# CEC1734_S0_2ZW register map
Vendor: Microchip Technology; Series: CEC; File version: 0
CPU: CM4 r1p0, little endian, MPU, FPU, 3 interrupt priority bits, 196 interrupts
Registers are 32-bit, read-write, reset 0x0 unless marked. A register's access mark holds for its fields unless they carry their own. Offsets are from the block's base; [hi:lo] are bit positions.

## SPT0 — SPI Peripheral Target Register.
Base 0x40007000; register names take the prefix SPT_
Same registers: SPT1 0x40006C00
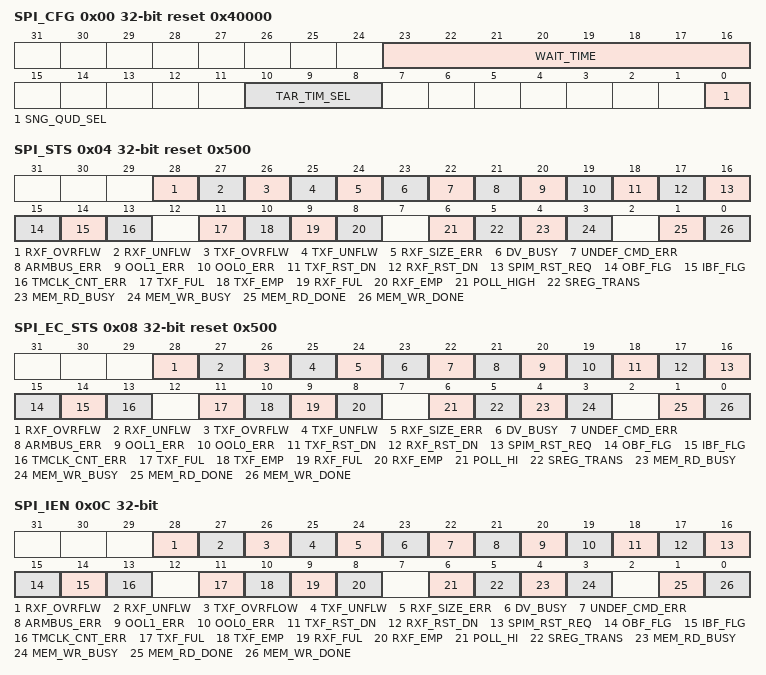
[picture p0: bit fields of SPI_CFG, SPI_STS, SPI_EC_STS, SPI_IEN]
0x00 SPI_CFG reset 0x40000 — SPI Peripheral Target Communication Configuration Register.
  [23:16] WAIT_TIME — These bits set the amount of wait time in cycles before transmitting data back to master. During this wait time status bits will be transmitted
  [10:8] TAR_TIM_SEL — Turn Around Time select for Quad wire mode. 0h = 1 cycle. 1h = 2 cycles. 2h = 4 cycles. 3h = 8 cycles. Other values are reserved.
    0=TAR_TIME_1_CYCLE (1 cycle); 1=TAR_TIME_2_CYCLE (2 cycle); 2=TAR_TIME_4_CYCLE (4 cycle); 3=TAR_TIME_8_CYCLE (8 cycle)
  [0] SNG_QUD_SEL — This field defines the Single / Quad Wire mode of operation for SPI Peripheral Target block. 0 = Single Wire Slave SPI block operation. 1 = Quad Wire Slave SPI block operation.
0x04 SPI_STS reset 0x500 — SPI Peripheral Target Status Register.
  [28] RXF_OVRFLW — If SPI Master writes more than the space in the FIFO, the FIFO will flag an overflow error and data will not be stored.
  [27] RXF_UNFLW — If the SPI Peripheral Target reads RX FIFO when it is empty, RX FIFO Underflow flag will be set. This condition will never happen under normal situation.
  [26] TXF_OVRFLW — If Master doesn't read all of the data it requested from the posted read block cycle, than data will still be left in the FIFO. This will cause misalignment with the following transactions and a new read cycle can cause overflow.
  [25] TXF_UNFLW — If Master reads more than what is in FIFO, FIFO will flag an underflow error and the data returned will just be the last valid pointer value.
  [24] RXF_SIZE_ERR — If size requested is more than what Master provided and the Master terminates early error flag shut down request signal to ARM Bus. Size requested is less than what Master provided -- ignored and continue transaction, may be taking in garbage.
  [23] DV_BUSY — If the Master requested a transaction whose destination is busy the request is ignored. Should use the poll or wait for interrupts.
  [22] UNDEF_CMD_ERR — Undefined Command Error: The command received from the master isn't defined.
  [21] ARMBUS_ERR — ARM Bus Error returned for the curren data transfer.
  [20] OOL1_ERR — This flag is set with the transfer address requested by the master is out of Limit 1 range or when the BAR is disabled.
  [19] OOL0_ERR — This flag is set with the transfer address requested by the master is out of Limit 0 range or when the BAR is disabled.
  [18] TXF_RST_DN — Set after the SPI Master initiates a TX FIFO reset and the reset has been processed. FIFO is cleared.
  [17] RXF_RST_DN — Set after the SPI Master initiates a RX FIFO reset and the reset has been processed. FIFO is cleared.
  [16] SPIM_RST_REQ — Set when the SPI Master Requested a Configuration Reset.
  [15] OBF_FLG — Set when the EC writes to the Output Buffer signaling there is data for the Host to read.
  [14] IBF_FLG — Set when the Host writes to the Input Buffer signaling there is data for the EC to read.
  [13] TMCLK_CNT_ERR — This bit is set when the SPI Clock Count Test Mode is set and there is an uneven amount of clocks.
  [11] TXF_FUL — The TX FIFO is full of data that was read from Memory.
  [10] TXF_EMP — Signifies SPI Master has read the data requested from Memory. Can be used to show there is data the SPI Master has requested and not been read yet. New read transactions will be aligned.
  [9] RXF_FUL — The RX FIFO is full of data to be written to Memory.
  [8] RXF_EMP — Signifies all Memory write transactions for the SPI Masters requested size have been performed. New transactions are allowed.
  [6] POLL_HIGH — If this bit is set, then something in the high 16-bit of status register is set and needs to be checked. SPI Master should take action to clear this.
  [5] SREG_TRANS — When an SREG transaction is currently being processed.
  [4] MEM_RD_BUSY — When an Memory Read transaction is currently being processed.
  [3] MEM_WR_BUSY — When an Memory Write transaction is currently being processed.
  [1] MEM_RD_DONE — When the ARM BUS side has fully finished writing the last written DWord to the FIFO for a set of data read from Memory for Posted Reads. - cleared with new Read request.
  [0] MEM_WR_DONE — When the ARM BUS side has fully finished the last transaction from the FIFO to write the data to Memory for Posted Writes . Clear with new Write request.
0x08 SPI_EC_STS reset 0x500 — SPI Peripheral Target EC Status Register.
  [28] RXF_OVRFLW — If SPI Master writes more than the space in the FIFO, the FIFO will flag an overflow error and data will not be stored.
  [27] RXF_UNFLW — If the SPI Peripheral Target reads RX FIFO when it is empty, RX FIFO Underflow flag will be set. This condition will never happen under normal situation.
  [26] TXF_OVRFLW — If Master doesn't read all of the data it requested from the posted read block cycle, than data will still be left in the FIFO. This will cause misalignment with the following transactions and a new read cycle can cause overflow.
  [25] TXF_UNFLW — If Master reads more than what is in FIFO, FIFO will flag an underflow error and the data returned will just be the last valid pointer value.
  [24] RXF_SIZE_ERR — If size requested is more than what Master provided and the Master terminates early error flag shut down request signal to ARM Bus. Size requested is less than what Master provided -- ignored and continue transaction, may be taking in garbage.
  [23] DV_BUSY — If the Master requested a transaction whose destination is busy the request is ignored. Should use the poll or wait for interrupts.
  [22] UNDEF_CMD_ERR — Undefined Command Error: The command received from the master isn't defined.
  [21] ARMBUS_ERR — ARM Bus Error returned for the curren data transfer.
  [20] OOL1_ERR — This flag is set with the transfer address requested by the master is out of Limit 1 range or when the BAR is disabled.
  [19] OOL0_ERR — This flag is set with the transfer address requested by the master is out of Limit 0 range or when the BAR is disabled.
  [18] TXF_RST_DN — Set after the SPI Master initiates a TX FIFO reset and the reset has been processed. FIFO is cleared.
  [17] RXF_RST_DN — Set after the SPI Master initiates a RX FIFO reset and the reset has been processed. FIFO is cleared.
  [16] SPIM_RST_REQ — Set when the SPI Master Requested a Configuration Reset.
  [15] OBF_FLG — Set when the EC writes to the Output Buffer signaling there is data for the Host to read.
  [14] IBF_FLG — Set when the Host writes to the Input Buffer signaling there is data for the EC to read.
  [13] TMCLK_CNT_ERR — This bit is set when the SPI Clock Count Test Mode is set and there is an uneven amount of clocks.
  [11] TXF_FUL — The TX FIFO is full of data that was read from Memory.
  [10] TXF_EMP — Signifies SPI Master has read the data requested from Memory. Can be used to show there is data the SPI Master has requested and not been read yet. New read transactions will be aligned.
  [9] RXF_FUL — The RX FIFO is full of data to be written to Memory.
  [8] RXF_EMP — Signifies all Memory write transactions for the SPI Masters requested size have been performed. New transactions are allowed.
  [6] POLL_HI — If this bit is set, then something in the high 16-bit of status register is set and needs to be checked. SPI Master should take action to clear this.
  [5] SREG_TRANS — When an SREG transaction is currently being processed.
  [4] MEM_RD_BUSY — When an Memory Read transaction is currently being processed.
  [3] MEM_WR_BUSY — When an Memory Write transaction is currently being processed.
  [1] MEM_RD_DONE — When the ARM BUS side has fully finished writing the last written DWord to the FIFO for a set of data read from Memory for Posted Reads. - cleared with new Read request.
  [0] MEM_WR_DONE — When the ARM BUS side has fully finished the last transaction from the FIFO to write the data to Memory for Posted Writes .- clear with new Write request.
0x0C SPI_IEN — SPI Peripheral Target Interrupt Enable Register.
  [28] RXF_OVRFLW — Enable RX FIFO Overflow Interrupt to SPI Master.
  [27] RXF_UNFLW — Enable RX FIFO Underflow Interrupt to SPI Master.
  [26] TXF_OVRFLOW — Enable TX FIFO Overflow Interrupt to SPI Master.
  [25] TXF_UNFLW — Enable TX FIFO Underflow Interrupt to SPI Master.
  [24] RXF_SIZE_ERR — Enable RX FIFO SIZE Error Interrupt to SPI Master.
  [23] DV_BUSY — Enable Device Busy Interrupt to SPI Master.
  [22] UNDEF_CMD_ERR — Enable Undefined Command Error Interrupt to SPI Master.
  [21] ARMBUS_ERR — Enable AHB BUS Error Interrupt to SPI Master.
  [20] OOL1_ERR — Enable Out Of Limit 1 Error Interrupt to SPI Master.
  [19] OOL0_ERR — Enable Out Of Limit 0 Error Interrupt to SPI Master.
  [18] TXF_RST_DN — Enable TX FIFO Reset Done Interrupt to SPI Master.
  [17] RXF_RST_DN — Enable RX FIFO Reset Done Interrupt to SPI Master.
  [16] SPIM_RST_REQ — Enable SPI Master Request Reset Interrupt to SPI Master.
  [15] OBF_FLG — Enable Output Buffer signaling Interrupt to SPI Master.
  [14] IBF_FLG — Enable Input Buffer Signaling Interrupt to SPI Master.
  [13] TMCLK_CNT_ERR — Enable Test Mode SPI Clock Count Error Interrupt to SPI Master.
  [11] TXF_FUL — Enable TX FIFI FULL Interrupt to SPI Master.
  [10] TXF_EMP — Enable TX FIFO Empty Interrupt to SPI Master.
  [9] RXF_FUL — Enable RX FIFO Full Interrupt to SPI Master.
  [8] RXF_EMP — Enable SREG RX FIFO Empty Interrupt to SPI Master.
  [6] POLL_HI — Enable Poll High Request Interrupt to SPI Master.
  [5] SREG_TRANS — Enable SREG Trans Busy Interrupt to SPI Master.
  [4] MEM_RD_BUSY — Enable Memory Read Busy Interrupt to SPI Master.
  [3] MEM_WR_BUSY — Enable Memory Write Busy Interrupt to SPI Master.
  [1] MEM_RD_DONE — Enable Memory Read Done Interrupt to SPI Master.
  [0] MEM_WR_DONE — Enable Memory Write Done Interrupt to SPI Master.
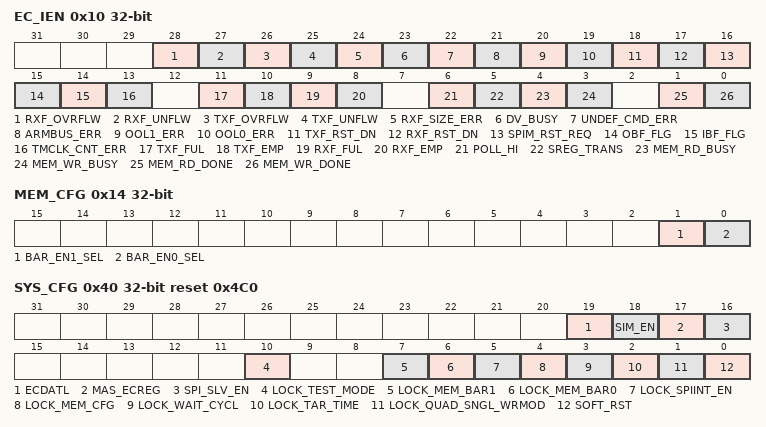
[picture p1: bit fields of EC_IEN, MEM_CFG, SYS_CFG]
0x10 EC_IEN — SPI Peripheral Target EC Interrupt Enable Register.
  [28] RXF_OVRFLW — Enable RX FIFO Overflow Interrupt to EC.
  [27] RXF_UNFLW — Enable RX FIFO Underflow Interrupt to EC.
  [26] TXF_OVRFLW — Enable TX FIFO Overflow Interrupt to EC.
  [25] TXF_UNFLW — Enable TX FIFO Underflow Interrupt to EC.
  [24] RXF_SIZE_ERR — Enable RX FIFO SIZE Error Interrupt to EC.
  [23] DV_BUSY — Enable Device Busy Interrupt to EC.
  [22] UNDEF_CMD_ERR — Enable Undefined Command Error Interrupt to EC.
  [21] ARMBUS_ERR — Enable AHB BUS Error Interrupt to EC.
  [20] OOL1_ERR — Enable Out Of Limit 1 Error Interrupt to EC.
  [19] OOL0_ERR — Enable Out Of Limit 0 Error Interrupt to EC.
  [18] TXF_RST_DN — Enable TX FIFO Reset Done Interrupt to EC.
  [17] RXF_RST_DN — Enable RX FIFO Reset Done Interrupt to EC.
  [16] SPIM_RST_REQ — Enable SPI Master Request Reset Interrupt to EC.
  [15] OBF_FLG — Enable Output Buffer signaling Interrupt to EC.
  [14] IBF_FLG — Enable Input Buffer Signaling Interrupt to EC.
  [13] TMCLK_CNT_ERR — Enable Test Mode SPI Clock Count Error Interrupt to EC.
  [11] TXF_FUL — Enable TX FIFI FULL Interrupt to EC.
  [10] TXF_EMP — Enable TX FIFO Empty Interrupt to EC.
  [9] RXF_FUL — Enable RX FIFO Full Interrupt to EC.
  [8] RXF_EMP — Enable SREG RX FIFO Empty Interrupt to EC.
  [6] POLL_HI — Enable Poll High Request Interrupt to EC.
  [5] SREG_TRANS — Enable SREG Trans Busy Interrupt to EC.
  [4] MEM_RD_BUSY — Enable Memory Read Busy Interrupt to EC.
  [3] MEM_WR_BUSY — Enable Memory Write Busy Interrupt to EC.
  [1] MEM_RD_DONE — Enable Memory Read Done Interrupt to EC.
  [0] MEM_WR_DONE — Enable Memory Write Done Interrupt to EC.
0x14 MEM_CFG — SPI Peripheral Target Memory Configuration Register.
  [1] BAR_EN1_SEL — Enables Region 1 operation. 0 = Disable Region 1. 1 = Enable Region 1.
  [0] BAR_EN0_SEL — Enables Region 0 operation. 0 = Disable Region 0. 1 = Enable Region 0.
0x18 MEM_BAR0 — SPI Peripheral Target Memory Base Address0 Register.
  [31:0] BAS_ADD0 — Base Address for Region 0.
0x1C MEM_WR_LIM0 — SPI Peripheral Target Memory Write LIMIT 0 Register.
  [14:0] LMT0 — Write Limit for Region 0.
0x20 MEM_RD_LIM0 — SPI Peripheral Target Memory Read LIMIT 0 Register.
  [14:0] LMT0 — Read Limit for Region 0.
0x24 MEM_BAR1 — SPI Peripheral Target Memory Base Address1 Register.
  [31:0] ADD1 — Base Address for Region 1.
0x28 MEM_WR_LIM1 — SPI Peripheral Target Memory Write LIMIT 1 Register.
  [14:0] LMT1 — Write Limit for Region 1.
0x2C MEM_RD_LIM1 — SPI Peripheral Target Memory Read LIMIT 1 Register.
  [14:0] LMT1 — Read Limit for Region 1.
0x30 RXF_HOST_BAR ro — SPI Peripheral Target RX FIFO Host Bar Register.
  [15:0] BAR — RX FIFO Host Bar Register.
0x34 RXF_BYTE_CNT ro — SPI Peripheral Target RX FIFO Byte Counter Register.
  [14:0] BCNT — RX FIFO Byte Count Register.
0x38 TXF_HOST_BAR ro — SPI Peripheral Target TX FIFO Host Bar Register.
  [15:0] BAR — TX FIFO Host Bar Register.
0x3C TXF_BYTE_CNT ro — SPI Peripheral Target TX FIFO Byte Counter Register.
  [14:0] BCNT — TX FIFO Byte Count Register.
0x40 SYS_CFG reset 0x4C0 — SPI Peripheral Target System Configuration Register.
  [19] ECDATL — Notification to TX FIFO Engine that data is available for AHB Transfer. This register but is cleared by Hardware at the end of the transaction, with SPI_CS_N de-assertion. (R/WC).
  [18] SIM_EN — Enable SPI Peripheral Target Simple Mode operation.
  [17] MAS_ECREG — Fixed in hardware to 1
  [16] SPI_SLV_EN — Enable / Disable SPI Peripheral Target Block. 0 = Disable SPI Peripheral Target module. 1 = Enable SPI Peripheral Target module.
  [10] LOCK_TEST_MODE — Lock TEST Mode register, write access from SPI Master.
  [7] LOCK_MEM_BAR1 — Lock Memory Bar 1 register, write access from SPI Master.
  [6] LOCK_MEM_BAR0 — Lock Memory Bar 0 register, write access from SPI Master.
  [5] LOCK_SPIINT_EN — Lock SPI Interrupt Enable register, write access from SPI Master.
  [4] LOCK_MEM_CFG — Lock Memory Configuration register, write access from SPI Master.
  [3] LOCK_WAIT_CYCL — Lock Wait Cycle bits, write access from SPI Master.
  [2] LOCK_TAR_TIME — Lock Tar Time bit, write access from SPI Master.
  [1] LOCK_QUAD_SNGL_WRMOD — Lock Quad / Single Write Mode bit, write access from SPI Master.
  [0] SOFT_RST — Soft reset for entire SPI Peripheral Target Block. This bit is self clearing.
0x44 SPIM2EC_MBX — SPI Peripheral Target Master to EC Mailbox Register.
  [31:0] M2EC — Write only register for the Host. When data is written to this register the IBF Flag is set. EC can read the data and writes of 0xFFFF will clear this register. Any form of read will clear the flag for this register.
0x48 EC2SPIM_MBX — SPI Peripheral Target Master to EC Mailbox Register.
  [31:0] EC2M — Read only register for the Host. When data is written to this register the OBF Flag is set. Host can read the data and writes of 0xFFFF_FFFF will clear this register, also clearing the flag. Any form of read will clear the flag for this register

## Notices in the file
Copyright (c) 2023 Microchip Technology Inc.
SPDX-License-Identifier: Apache-2.0
Licensed under the Apache License, Version 2.0 (the "License");
you may not use this file except in compliance with the License.
You may obtain a copy of the License at
http://www.apache.org/licenses/LICENSE-2.0
Unless required by applicable law or agreed to in writing, software
distributed under the License is distributed on an "AS IS" BASIS,
WITHOUT WARRANTIES OR CONDITIONS OF ANY KIND, either express or implied.
See the License for the specific language governing permissions and
limitations under the License.
